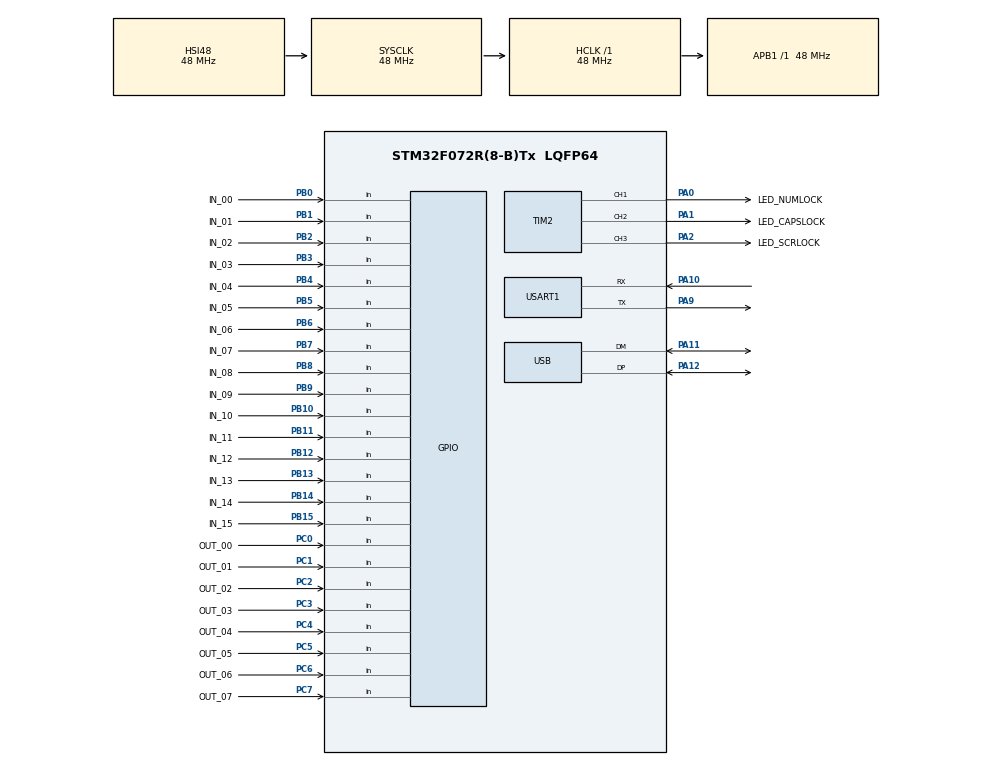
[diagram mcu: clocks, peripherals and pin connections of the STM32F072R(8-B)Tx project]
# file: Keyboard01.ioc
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Mcu.Family=STM32F0
Mcu.Name=STM32F072R(8-B)Tx
Mcu.Package=LQFP64
NVIC.TIM3_IRQn=true\:0\:0\:false\:false\:true\:true\:true
NVIC.USB_IRQn=true\:0\:0\:false\:false\:true\:false\:true
PA0.GPIO_Label=LED_NUMLOCK
PA0.Signal=S_TIM2_CH1_ETR
PA1.GPIO_Label=LED_CAPSLOCK
PA1.Signal=S_TIM2_CH2
PA10.Mode=Asynchronous
PA10.Signal=USART1_RX
PA11.Mode=Device
PA11.Signal=USB_DM
PA12.Mode=Device
PA12.Signal=USB_DP
PA13.Mode=Serial_Wire
PA13.Signal=SYS_SWDIO
PA14.Mode=Serial_Wire
PA14.Signal=SYS_SWCLK
PA2.GPIO_Label=LED_SCRLOCK
PA2.Signal=S_TIM2_CH3
PA9.Mode=Asynchronous
PA9.Signal=USART1_TX
PB0.GPIO_Label=IN_00
PB0.GPIO_PuPd=GPIO_PULLDOWN
PB0.Signal=GPIO_Input
PB1.GPIO_Label=IN_01
PB1.GPIO_PuPd=GPIO_PULLDOWN
PB1.Signal=GPIO_Input
PB10.GPIO_Label=IN_10
PB10.GPIO_PuPd=GPIO_PULLDOWN
PB10.Signal=GPIO_Input
PB11.GPIO_Label=IN_11
PB11.GPIO_PuPd=GPIO_PULLDOWN
PB11.Signal=GPIO_Input
PB12.GPIO_Label=IN_12
PB12.GPIO_PuPd=GPIO_PULLDOWN
PB12.Signal=GPIO_Input
PB13.GPIO_Label=IN_13
PB13.GPIO_PuPd=GPIO_PULLDOWN
PB13.Signal=GPIO_Input
PB14.GPIO_Label=IN_14
PB14.GPIO_PuPd=GPIO_PULLDOWN
PB14.Signal=GPIO_Input
PB15.GPIO_Label=IN_15
PB15.GPIO_PuPd=GPIO_PULLDOWN
PB15.Signal=GPIO_Input
PB2.GPIO_Label=IN_02
PB2.GPIO_PuPd=GPIO_PULLDOWN
PB2.Signal=GPIO_Input
PB3.GPIO_Label=IN_03
PB3.GPIO_PuPd=GPIO_PULLDOWN
PB3.Signal=GPIO_Input
PB4.GPIO_Label=IN_04
PB4.GPIO_PuPd=GPIO_PULLDOWN
PB4.Signal=GPIO_Input
PB5.GPIO_Label=IN_05
PB5.GPIO_PuPd=GPIO_PULLDOWN
PB5.Signal=GPIO_Input
PB6.GPIO_Label=IN_06
PB6.GPIO_PuPd=GPIO_PULLDOWN
PB6.Signal=GPIO_Input
PB7.GPIO_Label=IN_07
PB7.GPIO_PuPd=GPIO_PULLDOWN
PB7.Signal=GPIO_Input
PB8.GPIO_Label=IN_08
PB8.GPIO_PuPd=GPIO_PULLDOWN
PB8.Signal=GPIO_Input
PB9.GPIO_Label=IN_09
PB9.GPIO_PuPd=GPIO_PULLDOWN
PB9.Signal=GPIO_Input
PC0.GPIO_Label=OUT_00
PC0.Signal=GPIO_Input
PC1.GPIO_Label=OUT_01
PC1.Signal=GPIO_Input
PC2.GPIO_Label=OUT_02
PC2.Signal=GPIO_Input
PC3.GPIO_Label=OUT_03
PC3.Signal=GPIO_Input
PC4.GPIO_Label=OUT_04
PC4.Signal=GPIO_Input
PC5.GPIO_Label=OUT_05
PC5.Signal=GPIO_Input
PC6.GPIO_Label=OUT_06
PC6.Signal=GPIO_Input
PC7.GPIO_Label=OUT_07
PC7.Signal=GPIO_Input
ProjectManager.HeapSize=0x200
ProjectManager.StackSize=0x400
ProjectManager.TargetToolchain=STM32CubeIDE
RCC.AHBFreq_Value=48000000
RCC.APB1Freq_Value=48000000
RCC.APB1TimFreq_Value=48000000
RCC.HCLKFreq_Value=48000000
RCC.SYSCLKFreq_VALUE=48000000
RCC.SYSCLKSource=RCC_SYSCLKSOURCE_HSI48
SH.S_TIM2_CH1_ETR.0=TIM2_CH1,PWM Generation1 CH1
SH.S_TIM2_CH2.0=TIM2_CH2,PWM Generation2 CH2
SH.S_TIM2_CH3.0=TIM2_CH3,PWM Generation3 CH3
TIM2.Channel-PWM\ Generation1\ CH1=TIM_CHANNEL_1
TIM2.Channel-PWM\ Generation2\ CH2=TIM_CHANNEL_2
TIM2.Channel-PWM\ Generation3\ CH3=TIM_CHANNEL_3
TIM3.AutoReloadPreload=TIM_AUTORELOAD_PRELOAD_ENABLE
TIM3.Period=99
TIM3.Prescaler=479
USART1.VirtualMode-Asynchronous=VM_ASYNC
USB_DEVICE.CLASS_NAME_FS=HID
USB_DEVICE.VirtualMode=Hid
USB_DEVICE.VirtualModeFS=Hid_FS
VP_TIM3_VS_ClockSourceINT.Mode=Internal
VP_USB_DEVICE_VS_USB_DEVICE_HID_FS.Mode=HID_FS
board=custom

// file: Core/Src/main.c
/* USER CODE BEGIN Header */
/**
 ******************************************************************************
 * @file           : main.c
 * @brief          : Main program body
 ******************************************************************************
 * @attention
 *
 * <h2><center>&copy; Copyright (c) 2020 STMicroelectronics.
 * All rights reserved.</center></h2>
 *
 * This software component is licensed by ST under BSD 3-Clause license,
 * the "License"; You may not use this file except in compliance with the
 * License. You may obtain a copy of the License at:
 *                        opensource.org/licenses/BSD-3-Clause
 *
 ******************************************************************************
 */
/* USER CODE END Header */

#include "main.h"
#include "usb_device.h"

/* USER CODE BEGIN Includes */
#include "usbd_hid.h"
#include "keyscan.h"
/* USER CODE END Includes */

TIM_HandleTypeDef htim2;
TIM_HandleTypeDef htim3;

UART_HandleTypeDef huart1;

/* USER CODE BEGIN PV */
extern USBD_HandleTypeDef hUsbDeviceFS;
/* USER CODE END PV */

void SystemClock_Config(void);
static void MX_GPIO_Init(void);
static void MX_TIM2_Init(void);
static void MX_USART1_UART_Init(void);
static void MX_TIM3_Init(void);

/* USER CODE BEGIN 0 */
int __io_putchar(int ch) {
    HAL_UART_Transmit(&huart1, (uint8_t*) &ch, 1, 0xFFFF);
    return ch;
}
/* USER CODE END 0 */

int main(void) {
    /* USER CODE BEGIN 1 */
//    struct keyboardHID_t keyboardHID;
//    keyboardHID.modifiers = 0;
//    keyboardHID.reserved = 0;
//    for (int i = 0; i < 6; i++) {
//        keyboardHID.key[i] = 0;
//    }
    /* USER CODE END 1 */

    /* MCU Configuration--------------------------------------------------------*/

    /* Reset of all peripherals, Initializes the Flash interface and the Systick. */
    HAL_Init();

    /* Configure the system clock */
    SystemClock_Config();

    /* Initialize all configured peripherals */
    MX_GPIO_Init();
    MX_TIM2_Init();
    MX_USART1_UART_Init();
    MX_USB_DEVICE_Init();
    MX_TIM3_Init();
    /* USER CODE BEGIN 2 */
    printf("Hello!\n");
    HAL_TIM_Base_Start_IT(&htim3);
//    HAL_Delay(1000);
//    keyboardHID.key[0] = 0x04; //a
//    keyboardHID.key[1] = 0x16; //s
//    keyboardHID.key[2] = 0x07; //d
//    keyboardHID.key[3] = 0x09; //f
//    keyboardHID.key[4] = 0x0A; //g
//    keyboardHID.key[5] = 0x0B; //h
//    USBD_HID_SendReport(&hUsbDeviceFS, &keyboardHID, sizeof(struct keyboardHID_t));
//    for (int i = 0; i < 6; i++) {
//        keyboardHID.key[i] = 0;
//    }
//    HAL_Delay(300);
//    USBD_HID_SendReport(&hUsbDeviceFS, &keyboardHID, sizeof(struct keyboardHID_t));
//    HAL_TIM_PWM_Start(&htim2, TIM_CHANNEL_1);
//    HAL_TIM_PWM_Start(&htim2, TIM_CHANNEL_2);
//    HAL_TIM_PWM_Start(&htim2, TIM_CHANNEL_3);
    /* USER CODE END 2 */

    /* Infinite loop */
    /* USER CODE BEGIN WHILE */
    while (1) {
        if (getLengthReport() > 0) {
            for (int i = 0; i < getLengthReport(); ++i) {
                struct keyboardHID_t tmp = getReport();
                USBD_HID_SendReport(&hUsbDeviceFS, &tmp, sizeof(struct keyboardHID_t));
                printf("T: %02X %02X %02X %02X %02X %02X\n", tmp.key[0], tmp.key[1], tmp.key[2], tmp.key[3], tmp.key[4], tmp.key[5]);
            }
        }
        /* USER CODE END WHILE */

    }
}

void SystemClock_Config(void) {
    RCC_OscInitTypeDef RCC_OscInitStruct = { 0 };
    RCC_ClkInitTypeDef RCC_ClkInitStruct = { 0 };
    RCC_PeriphCLKInitTypeDef PeriphClkInit = { 0 };

    /** Initializes the CPU, AHB and APB busses clocks
     */
    RCC_OscInitStruct.OscillatorType = RCC_OSCILLATORTYPE_HSI48;
    RCC_OscInitStruct.HSI48State = RCC_HSI48_ON;
    RCC_OscInitStruct.PLL.PLLState = RCC_PLL_NONE;
    if (HAL_RCC_OscConfig(&RCC_OscInitStruct) != HAL_OK) {
        Error_Handler();
    }
    /** Initializes the CPU, AHB and APB busses clocks
     */
    RCC_ClkInitStruct.ClockType = RCC_CLOCKTYPE_HCLK | RCC_CLOCKTYPE_SYSCLK | RCC_CLOCKTYPE_PCLK1;
    RCC_ClkInitStruct.SYSCLKSource = RCC_SYSCLKSOURCE_HSI48;
    RCC_ClkInitStruct.AHBCLKDivider = RCC_SYSCLK_DIV1;
    RCC_ClkInitStruct.APB1CLKDivider = RCC_HCLK_DIV1;

    if (HAL_RCC_ClockConfig(&RCC_ClkInitStruct, FLASH_LATENCY_1) != HAL_OK) {
        Error_Handler();
    }
    PeriphClkInit.PeriphClockSelection = RCC_PERIPHCLK_USB | RCC_PERIPHCLK_USART1;
    PeriphClkInit.Usart1ClockSelection = RCC_USART1CLKSOURCE_PCLK1;
    PeriphClkInit.UsbClockSelection = RCC_USBCLKSOURCE_HSI48;

    if (HAL_RCCEx_PeriphCLKConfig(&PeriphClkInit) != HAL_OK) {
        Error_Handler();
    }
}

static void MX_TIM2_Init(void) {

    TIM_MasterConfigTypeDef sMasterConfig = { 0 };
    TIM_OC_InitTypeDef sConfigOC = { 0 };

    htim2.Instance = TIM2;
    htim2.Init.Prescaler = 100;
    htim2.Init.CounterMode = TIM_COUNTERMODE_UP;
    htim2.Init.Period = 100;
    htim2.Init.ClockDivision = TIM_CLOCKDIVISION_DIV1;
    htim2.Init.AutoReloadPreload = TIM_AUTORELOAD_PRELOAD_DISABLE;
    if (HAL_TIM_PWM_Init(&htim2) != HAL_OK) {
        Error_Handler();
    }
    sMasterConfig.MasterOutputTrigger = TIM_TRGO_RESET;
    sMasterConfig.MasterSlaveMode = TIM_MASTERSLAVEMODE_DISABLE;
    if (HAL_TIMEx_MasterConfigSynchronization(&htim2, &sMasterConfig) != HAL_OK) {
        Error_Handler();
    }
    sConfigOC.OCMode = TIM_OCMODE_PWM1;
    sConfigOC.Pulse = 99;
    sConfigOC.OCPolarity = TIM_OCPOLARITY_HIGH;
    sConfigOC.OCFastMode = TIM_OCFAST_DISABLE;
    if (HAL_TIM_PWM_ConfigChannel(&htim2, &sConfigOC, TIM_CHANNEL_1) != HAL_OK) {
        Error_Handler();
    }
    if (HAL_TIM_PWM_ConfigChannel(&htim2, &sConfigOC, TIM_CHANNEL_2) != HAL_OK) {
        Error_Handler();
    }
    if (HAL_TIM_PWM_ConfigChannel(&htim2, &sConfigOC, TIM_CHANNEL_3) != HAL_OK) {
        Error_Handler();
    }
    HAL_TIM_MspPostInit(&htim2);

}

static void MX_TIM3_Init(void) {

    TIM_ClockConfigTypeDef sClockSourceConfig = { 0 };
    TIM_MasterConfigTypeDef sMasterConfig = { 0 };

    htim3.Instance = TIM3;
    htim3.Init.Prescaler = 479;
    htim3.Init.CounterMode = TIM_COUNTERMODE_UP;
    htim3.Init.Period = 99;
    htim3.Init.ClockDivision = TIM_CLOCKDIVISION_DIV1;
    htim3.Init.AutoReloadPreload = TIM_AUTORELOAD_PRELOAD_ENABLE;
    if (HAL_TIM_Base_Init(&htim3) != HAL_OK) {
        Error_Handler();
    }
    sClockSourceConfig.ClockSource = TIM_CLOCKSOURCE_INTERNAL;
    if (HAL_TIM_ConfigClockSource(&htim3, &sClockSourceConfig) != HAL_OK) {
        Error_Handler();
    }
    sMasterConfig.MasterOutputTrigger = TIM_TRGO_RESET;
    sMasterConfig.MasterSlaveMode = TIM_MASTERSLAVEMODE_DISABLE;
    if (HAL_TIMEx_MasterConfigSynchronization(&htim3, &sMasterConfig) != HAL_OK) {
        Error_Handler();
    }

}

static void MX_USART1_UART_Init(void) {

    huart1.Instance = USART1;
    huart1.Init.BaudRate = 115200;
    huart1.Init.WordLength = UART_WORDLENGTH_8B;
    huart1.Init.StopBits = UART_STOPBITS_1;
    huart1.Init.Parity = UART_PARITY_NONE;
    huart1.Init.Mode = UART_MODE_TX_RX;
    huart1.Init.HwFlowCtl = UART_HWCONTROL_NONE;
    huart1.Init.OverSampling = UART_OVERSAMPLING_16;
    huart1.Init.OneBitSampling = UART_ONE_BIT_SAMPLE_DISABLE;
    huart1.AdvancedInit.AdvFeatureInit = UART_ADVFEATURE_NO_INIT;
    if (HAL_UART_Init(&huart1) != HAL_OK) {
        Error_Handler();
    }

}

static void MX_GPIO_Init(void) {
    GPIO_InitTypeDef GPIO_InitStruct = { 0 };

    /* GPIO Ports Clock Enable */
    __HAL_RCC_GPIOC_CLK_ENABLE();
    __HAL_RCC_GPIOA_CLK_ENABLE();
    __HAL_RCC_GPIOB_CLK_ENABLE();

    /*Configure GPIO pins : OUT_00_Pin OUT_01_Pin OUT_02_Pin OUT_03_Pin
     OUT_04_Pin OUT_05_Pin OUT_06_Pin OUT_07_Pin */
    GPIO_InitStruct.Pin = OUT_00_Pin | OUT_01_Pin | OUT_02_Pin | OUT_03_Pin | OUT_04_Pin | OUT_05_Pin | OUT_06_Pin | OUT_07_Pin;
    GPIO_InitStruct.Mode = GPIO_MODE_INPUT;
    GPIO_InitStruct.Pull = GPIO_NOPULL;
    HAL_GPIO_Init(GPIOC, &GPIO_InitStruct);

    /*Configure GPIO pins : IN_00_Pin IN_01_Pin IN_02_Pin IN_10_Pin
     IN_11_Pin IN_12_Pin IN_13_Pin IN_14_Pin
     IN_15_Pin IN_03_Pin IN_04_Pin IN_05_Pin
     IN_06_Pin IN_07_Pin IN_08_Pin IN_09_Pin */
    GPIO_InitStruct.Pin = IN_00_Pin | IN_01_Pin | IN_02_Pin | IN_10_Pin | IN_11_Pin | IN_12_Pin | IN_13_Pin | IN_14_Pin | IN_15_Pin | IN_03_Pin | IN_04_Pin | IN_05_Pin | IN_06_Pin | IN_07_Pin | IN_08_Pin | IN_09_Pin;
    GPIO_InitStruct.Mode = GPIO_MODE_INPUT;
    GPIO_InitStruct.Pull = GPIO_PULLDOWN;
    HAL_GPIO_Init(GPIOB, &GPIO_InitStruct);

}

void Error_Handler(void) {
}

/************************ (C) COPYRIGHT STMicroelectronics *****END OF FILE****/
